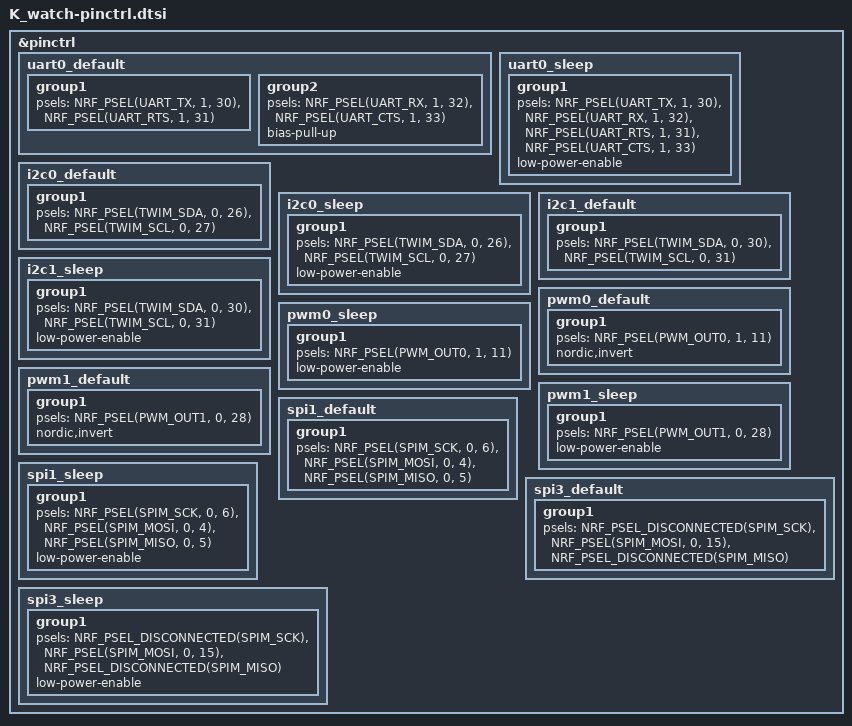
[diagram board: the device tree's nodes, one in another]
&pinctrl {
    uart0_default: uart0_default {
		group1 {
			psels = <NRF_PSEL(UART_TX, 1, 30)>,
				<NRF_PSEL(UART_RTS, 1, 31)>;
		};

		group2 {
			psels = <NRF_PSEL(UART_RX, 1, 32)>,
				<NRF_PSEL(UART_CTS, 1, 33)>;
			bias-pull-up;
		};
	};

	uart0_sleep: uart0_sleep {
		group1 {
			psels = <NRF_PSEL(UART_TX, 1, 30)>,
				<NRF_PSEL(UART_RX, 1, 32)>,
				<NRF_PSEL(UART_RTS, 1, 31)>,
				<NRF_PSEL(UART_CTS, 1, 33)>;
			low-power-enable;
		};
	};

    i2c0_default: i2c0_default {
		group1 {
			psels = <NRF_PSEL(TWIM_SDA, 0, 26)>,
				<NRF_PSEL(TWIM_SCL, 0, 27)>;
		};
	};

	i2c0_sleep: i2c0_sleep {
		group1 {
			psels = <NRF_PSEL(TWIM_SDA, 0, 26)>,
				<NRF_PSEL(TWIM_SCL, 0, 27)>;
			low-power-enable;
		};
	};

	i2c1_default: i2c1_default {
		group1 {
			psels = <NRF_PSEL(TWIM_SDA, 0, 30)>,
				<NRF_PSEL(TWIM_SCL, 0, 31)>;
		};
	};

	i2c1_sleep: i2c1_sleep {
		group1 {
			psels = <NRF_PSEL(TWIM_SDA, 0, 30)>,
				<NRF_PSEL(TWIM_SCL, 0, 31)>;
			low-power-enable;
		};
	};

    pwm0_default: pwm0_default {
		group1 {
			psels = <NRF_PSEL(PWM_OUT0, 1, 11)>;
			nordic,invert;
		};
	};

	pwm0_sleep: pwm0_sleep {
		group1 {
			psels = <NRF_PSEL(PWM_OUT0, 1, 11)>;
			low-power-enable;
		};
	};

	pwm1_default: pwm1_default {
		group1 {
			psels = <NRF_PSEL(PWM_OUT1, 0, 28)>;
			nordic,invert;
		};
	};

	pwm1_sleep: pwm1_sleep {
		group1 {
			psels = <NRF_PSEL(PWM_OUT1, 0, 28)>;
			low-power-enable;
		};
	};

    spi1_default: spi1_default {
		group1 {
			psels = <NRF_PSEL(SPIM_SCK, 0, 6)>,
				<NRF_PSEL(SPIM_MOSI, 0, 4)>,
				<NRF_PSEL(SPIM_MISO, 0, 5)>;
		};
	};

	spi1_sleep: spi1_sleep {
		group1 {
			psels = <NRF_PSEL(SPIM_SCK, 0, 6)>,
				<NRF_PSEL(SPIM_MOSI, 0, 4)>,
				<NRF_PSEL(SPIM_MISO, 0, 5)>;
			low-power-enable;
		};
	};

	spi3_default: spi3_default {
		group1 {
			psels = <NRF_PSEL_DISCONNECTED(SPIM_SCK)>,
				<NRF_PSEL(SPIM_MOSI, 0, 15)>,
				<NRF_PSEL_DISCONNECTED(SPIM_MISO)>;
		};
	};

	spi3_sleep: spi3_sleep {
		group1 {
			psels = <NRF_PSEL_DISCONNECTED(SPIM_SCK)>,
				<NRF_PSEL(SPIM_MOSI, 0, 15)>,
				<NRF_PSEL_DISCONNECTED(SPIM_MISO)>;
			low-power-enable;
		};
	};

};
